# cslr_dma_001 register map
Vendor: Texas Instruments
Peripheral module from a debugger description file (folder C5515).
Address unit: 16 bits
Registers are 16-bit, read-write, reset 0x0 unless marked. A register's access mark holds for its fields unless they carry their own. Offsets are as the file gives them; lines under a group give offsets from that group; [hi:lo] are bit positions; {n}, {i} and the like mark numbered series; 'fields as' and 'values as' point back to an identical list; <NAME> marks a mode.

## DMA — The DMA controller is used to move data among internal memory, external memory, and peripherals without intervention from the CPU and in the background of CPU operation. The DMA controller has four channels with identical registers.
{0x0+0x20*i} DMACH{i}SSAL (i=0..3) — Specifies the least-significant 16-bits of the 32-bit byte source address used by the DMA channel.
  [15:0] SSAL — Lower part of source start address (byte address).
{0x1+0x20*i} DMACH{i}SSAU (i=0..3) — Specifies the most-significant 16-bits of the 32-bit byte source address used by the DMA channel.
  [15:0] SSAU — Upper part of source start address (byte address).
{0x2+0x20*i} DMACH{i}DSAL (i=0..3) — Specifies the least-significant 16-bits of the 32-bit byte destination address used by the DMA channel.
  [15:0] DSAL — Lower part of destination start address (byte address).
{0x3+0x20*i} DMACH{i}DSAU (i=0..3) — Specifies the most-significant 16-bits of the 32-bit byte destination address used by the DMA channel.
  [15:0] DSAU — Upper part of destination start address (byte address).
0x04 DMACH0TCR1 — Specifies the size of the DMA transfer (in bytes).
  [15:0] LENGTH — Total size of data transfer in bytes. When Ping Pong mode is enabled, this is the size of the ping and pong transfer combined 0,1,2,3 = Reserved 4 65532 in increments of 4 * 2Burst Mode bytes
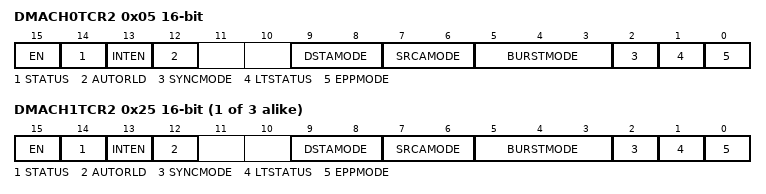
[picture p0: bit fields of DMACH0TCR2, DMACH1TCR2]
0x05 DMACH0TCR2 access not given — Controls the transfer context for the DMA channel.
  [15] EN rw — Channel enable bit. Use EN to enable or disable transfers in the channel. The DMA controller clears EN once a block transfer in the channel is complete.
    0=ENABLE (The channel is disabled. The channel cannot be serviced by the DMA controller. If DMA burst transfer is ongoing in the channel, the DMA controller allows the burst transfer to complete. Note: When you write a 0 to this bit, you must also write a 0 to the SYNCMODE bit.); 1=DISABLE (The channel is enabled. The channel can be serviced by the DMA in the next available time slot.)
  [14] STATUS rw — Channel status bit. This bit indicates the status of the DMA channel transfer. The DMA controller sets the channel STATUS bit to 1 if: - A nonzero value is written on LENGTH in DMACH0TR1. - A write access is performed to DMATCR2 and LENGTH has a nonzero value. The DMA controller clears the STATUS bit to 0 if: - The all the bytes specified by LENGTH in DMACH0TR1 have been transferred. - A value of 0 is written to LENGTH in DMACH0TR1.
    0=DONE (Corresponding DMA channel has transferred all the bytes specified by LENGTH in DMACH0TR1.); 1=ACTIVE (Corresponding DMA channel has not finished transferring all the bytes specified by LENGTH in DMACH0TR1.)
  [13] INTEN rw — CPU interrupt enable bit. The DMA channel is capable of generating a CPU interrupt when a block transfer is finished. In order for the CPU to receive the interrupt, the corresponding channel interrupt mask bit in the interrupt mask register (DMAIMR) must be set to 1.
    0=DISABLE (Disable channel interrupt.); 1=ENABLE (Enable channel interrupt.)
  [12] AUTORLD rw — Automatic reload bit. Once a transfer is finished, the DMA automatically reloads the transfer control register and the source and destination start address registers and restarts the transfer. Note: Automatic reload can only be used when SYNCMODE = 1.
    0=DISABLE (DMA transfer does not automatically reload.); 1=ENABLE (Upon completion of a full transfer, the registers are reloaded and the transfer is restarted.)
  [9:8] DSTAMODE rw — Destination addressing mode bits. DSTAMODE determines the addressing mode used by the DMA controller when it writes to the destination address.
    0=INCR (Automatic post increment. The destination byte address is incremented by four after each transfer.); 1=RSV1 (Reserved, do not use.); 2=CONST (Constant address.); 3=RSV3 (Reserved, do not use.)
  [7:6] SRCAMODE rw — Source addressing mode bits. SRCAMODE determines the addressing mode used by the DMA controller when it reads from the source address.
    0=INCR (Automatic post increment. The source byte address is incremented by four after each transfer.); 1=RSV1 (Reserved, do not use.); 2=CONST (Constant address.); 3=RSV3 (Reserved, do not use.)
  [5:3] BURSTMODE rw — Burst mode bits. These bits specify the number of double word transfers that each channel performs at once before the DMA controller moves on to the next active channel. Note: The burst mode selected must always be less than or equal to the number of bytes specified in DMACH0TR1.
  [2] SYNCMODE rw — Synchronization mode bit. SYNCEVT bits in DMACESRn determine which event in the DSP (for example, a timer countdown) initiates a DMA transfer in the channel. Multiple channels can have the same SYNCEVT value; in other words, one synchronization event can initiate activity in multiple channels. On each sync event, the DMA transfers the number of words specified by the by the BURSTMODE bits. For example, BURSTMODE = 010b, the DMA will transfer a total of 16 bytes per sync event. A DSP reset selects SYNCMODE = 0 (no synchronization). When SYNCMODE = 0, the DMA controller does not wait for a synchronization event before beginning a DMA transfer in the channel; channel activity begins as soon as the channel is enabled (EN = 1).
    0=NOSYNC (Synchronization is disabled, the DMA controller does not wait for a synchronization event before beginning a DMA transfer. Note: When you write a 0 to the EN bit, you must also write a 0 to this bit.); 1=SYNC (Activity in the DMA controller is synchronized to the event specified in the SYNCEVT bits of DMACESRn. Note: When you set this bit to 1, you must also write a 1 to the EN bit.)
  [1] LTSTATUS rw — Indicates the most recent completed transfer set. This status bit is valid when the Enable Ping Pong Mode bit is set. 0 = The last completed transfer was to/from the Ping buffer 1 = The last completed transfer was to/from the Pong buffer
    0=PING; 1=PONG
  [0] EPPMODE rw — Enable ping pong mode. 0 = Ping Pong Mode is disabled 1 = Ping Pong Mode is enabled
    0=DISABLE; 1=ENABLE
0x24 DMACH1TCR1 — Specifies the size of the DMA transfer (in bytes).
  fields as DMACH0TCR1
{0x5+0x20*i} DMACH{i}TCR2 access not given (i=1..3) — Controls the transfer context for the DMA channel.
  [15] EN rw — Channel enable bit. Use EN to enable or disable transfers in the channel. The DMA controller clears EN once a block transfer in the channel is complete.
    values as DMACH0TCR2.EN
  [14] STATUS rw — Channel status bit. This bit indicates the status of the DMA channel transfer. The DMA controller sets the channel STATUS bit to 1 if: - A nonzero value is written on LENGTH in DMACH{i}TR1. - A write access is performed to DMATCR2 and LENGTH has a nonzero value. The DMA controller clears the STATUS bit to 0 if: - The all the bytes specified by LENGTH in DMACH{i}TR1 have been transferred. - A value of 0 is written to LENGTH in DMACH{i}TR1.
    0=DONE (Corresponding DMA channel has transferred all the bytes specified by LENGTH in DMACH{i}TR1.); 1=ACTIVE (Corresponding DMA channel has not finished transferring all the bytes specified by LENGTH in DMACH{i}TR1.)
  [13] INTEN rw — CPU interrupt enable bit. The DMA channel is capable of generating a CPU interrupt when a block transfer is finished. In order for the CPU to receive the interrupt, the corresponding channel interrupt mask bit in the interrupt mask register (DMAIMR) must be set to 1.
    values as DMACH0TCR2.INTEN
  [12] AUTORLD rw — Automatic reload bit. Once a transfer is finished, the DMA automatically reloads the transfer control register and the source and destination start address registers and restarts the transfer. Note: Automatic reload can only be used when SYNCMODE = 1.
    values as DMACH0TCR2.AUTORLD
  [9:8] DSTAMODE rw — Destination addressing mode bits. DSTAMODE determines the addressing mode used by the DMA controller when it writes to the destination address.
    values as DMACH0TCR2.DSTAMODE
  [7:6] SRCAMODE rw — Source addressing mode bits. SRCAMODE determines the addressing mode used by the DMA controller when it reads from the source address.
    values as DMACH0TCR2.SRCAMODE
  [5:3] BURSTMODE rw — Burst mode bits. These bits specify the number of byte transfers that each channel performs at once before the DMA controller moves on to the next active channel. Note: The burst mode selected must always be less than or equal to the number of bytes specified in DMACH{i}TR1.
    0=1DWORD (1 double word (4 bytes).); 1=2DWORDS (2 double words (8 bytes).); 2=4DWORDS (4 double words (16 bytes).); 3=8DWORDS (8 double words (32 bytes).); 4=16DWORDS (16 double words (64 bytes).); 5=RSV5 (Reserved, do not use.); 6=RSV6 (Reserved, do not use.); 7=RSV7 (Reserved, do not use.)
  [2] SYNCMODE rw — Synchronization mode bit. SYNCEVT bits in DMACESRn determine which event in the DSP (for example, a timer countdown) initiates a DMA transfer in the channel. Multiple channels can have the same SYNCEVT value; in other words, one synchronization event can initiate activity in multiple channels. On each sync event, the DMA transfers the number of words specified by the by the BURSTMODE bits. For example, BURSTMODE = 010b, the DMA will transfer a total of 16 bytes per sync event. A DSP reset selects SYNCMODE = 0 (no synchronization). When SYNCMODE = 0, the DMA controller does not wait for a synchronization event before beginning a DMA transfer in the channel; channel activity begins as soon as the channel is enabled (EN = 1).
    values as DMACH0TCR2.SYNCMODE
  [1] LTSTATUS rw — Indicates the most recent completed transfer set. This status bit is valid when the Enable Ping Pong Mode bit is set. 0 = The last completed transfer was to/from the Ping buffer 1 = The last completed transfer was to/from the Pong buffer
    0=PING; 1=PONG
  [0] EPPMODE rw — Enable ping pong mode. 0 = Ping Pong Mode is disabled 1 = Ping Pong Mode is enabled
    0=DISABLE; 1=ENABLE
0x44 DMACH2TCR1 — Specifies the size of the DMA transfer (in bytes).
  [15:0] LENGTH — Total size of data transfer in bytes. When Ping Pong mode is enabled, this is the size of the ping and pong transfer combined 0,1,2,3 = Reserved 4 65532 in increments of 4 * 2Burst Mode bytes.
0x64 DMACH3TCR1 — Specifies the size of the DMA transfer (in bytes).
  fields as DMACH0TCR1
